# SIMG301M114LGH register map
Vendor: Silicon Labs; Series: Si; File version: B
Registers are 32-bit, read-write, reset 0x0 unless marked. A register's access mark holds for its fields unless they carry their own. Offsets are from the block's base; [hi:lo] are bit positions; {n}, {i} and the like mark numbered series; 'fields as' and 'values as' point back to an identical list.

## CMU_NS — CMU_NS Registers
Base 0x40804000
Same registers: CMU_S 0x50804000
0x00 IPVERSION ro reset 0x8
  [31:0] IPVERSION — IP Version ID
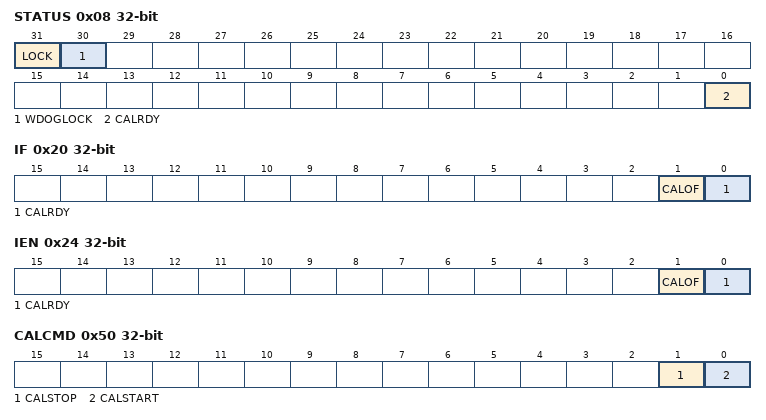
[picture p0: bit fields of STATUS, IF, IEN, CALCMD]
0x08 STATUS ro
  [31] LOCK — Configuration Lock Status
    0=UNLOCKED (Configuration lock is unlocked); 1=LOCKED (Configuration lock is locked)
  [30] WDOGLOCK — Configuration Lock Status for WDOG
    0=UNLOCKED (WDOG configuration lock is unlocked); 1=LOCKED (WDOG configuration lock is locked)
  [0] CALRDY — Calibration Ready
0x10 LOCK wo reset 0x93F7
  [15:0] LOCKKEY — Configuration Lock Key
    0x93F7=UNLOCK (Write this value to unlock)
0x14 WDOGLOCK wo reset 0x5257
  fields as LOCK
0x20 IF
  [1] CALOF — Calibration Overflow Interrupt Flag
  [0] CALRDY — Calibration Ready Interrupt Flag
0x24 IEN
  [1] CALOF — Calibration Overflow Interrupt Enable
  [0] CALRDY — Calibration Ready Interrupt Enable
0x50 CALCMD wo
  [1] CALSTOP — Calibration Stop
  [0] CALSTART — Calibration Start
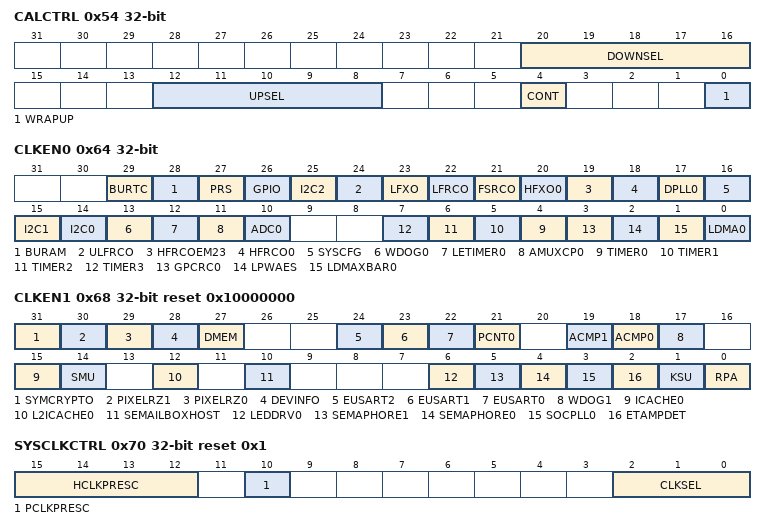
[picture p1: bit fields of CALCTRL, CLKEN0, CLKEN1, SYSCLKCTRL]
0x54 CALCTRL
  [20:16] DOWNSEL — Calibration Down-counter Select
    0=DISABLED (Down-counter is not clocked); 1=HCLK (HCLK is clocking down-counter); 2=PRS (PRS CMU_CALDN consumer is clocking down-counter); 3=HFXO (HFXO is clocking down-counter); 4=LFXO (LFXO is clocking down-counter); 5=HFRCODPLL (HFRCODPLL is clocking down-counter); 6=HFRCOEM23 (HFRCOEM23 is clocking down-counter); 7=FSRCO (FSRCO is clocking down-counter); 8=LFRCO (LFRCO is clocking down-counter); 9=ULFRCO (ULFRCO is clocking down-counter); 10=HFRCOLPW (HFRCOLPW is clocking down-counter); 11=SOCPLL (SOCPLL is clocking down-counter)
  [12:8] UPSEL — Calibration Up-counter Select
    0=DISABLED (Up-counter is not clocked); 1=HCLK (HCLK is clocking up-counter); 2=PRS (PRS is clocking down-counter); 3=HFXO (HFXO is clocking up-counter); 4=LFXO (LFXO is clocking up-counter); 5=HFRCODPLL (HFRCODPLL is clocking up-counter); 6=HFRCOEM23 (HFRCOEM23 is clocking up-counter); 7=FSRCO (FSRCO is clocking up-counter); 8=LFRCO (LFRCO is clocking up-counter); 9=ULFRCO (ULFRCO is clocking up-counter); 10=HFRCOLPW (HFRCOLPW is clocking up-counter); 11=SOCPLL (SOCPLL is clocking up-counter)
  [4] CONT — Continuous Calibration
  [0] WRAPUP — Wrap around Up-counter
0x58 CALCNT ro
  [23:0] CALCNT — Calibration Result Counter Value
0x5C CALTOP
  [23:0] CALTOP — Calibration Counter Top Value
0x64 CLKEN0
  [29] BURTC — Enable Bus Clock
  [28] BURAM — Enable Bus Clock
  [27] PRS — Enable Bus Clock
  [26] GPIO — Enable Bus Clock
  [25] I2C2 — Enable Bus Clock
  [24] ULFRCO — Enable Bus Clock
  [23] LFXO — Enable Bus Clock
  [22] LFRCO — Enable Bus Clock
  [21] FSRCO — Enable Bus Clock
  [20] HFXO0 — Enable Bus Clock
  [19] HFRCOEM23 — Enable Bus Clock
  [18] HFRCO0 — Enable Bus Clock
  [17] DPLL0 — Enable Bus Clock
  [16] SYSCFG — Enable Bus Clock
  [15] I2C1 — Enable Bus Clock
  [14] I2C0 — Enable Bus Clock
  [13] WDOG0 — Enable Bus Clock
  [12] LETIMER0 — Enable Bus Clock
  [11] AMUXCP0 — Enable Bus Clock
  [10] ADC0 — Enable Bus Clock
  [n+4] TIMER{n} (n=0..3) — Enable Bus Clock
  [3] GPCRC0 — Enable Bus Clock
  [2] LPWAES — Enable Bus Clock
  [1] LDMAXBAR0 — Enable Bus Clock
  [0] LDMA0 — Enable Bus Clock
0x68 CLKEN1 reset 0x10000000
  [31] SYMCRYPTO — Enable Bus Clock
  [30] PIXELRZ1 — Enable Bus Clock
  [29] PIXELRZ0 — Enable Bus Clock
  [28] DEVINFO — Enable Bus Clock
  [27] DMEM — Enable Bus Clock
  [24] EUSART2 — Enable Bus Clock
  [23] EUSART1 — Enable Bus Clock
  [22] EUSART0 — Enable Bus Clock
  [21] PCNT0 — Enable Bus Clock
  [19] ACMP1 — Enable Bus Clock
  [18] ACMP0 — Enable Bus Clock
  [17] WDOG1 — Enable Bus Clock
  [15] ICACHE0 — Enable Bus Clock
  [14] SMU — Enable Bus Clock
  [12] L2ICACHE0 — Enable Bus Clock
  [10] SEMAILBOXHOST — Enable Bus Clock
  [6] LEDDRV0 — Enable Bus Clock
  [5] SEMAPHORE1 — Enable Bus Clock
  [4] SEMAPHORE0 — Enable Bus Clock
  [3] SOCPLL0 — Enable Bus Clock
  [2] ETAMPDET — Enable Bus Clock
  [1] KSU — Enable Bus Clock
  [0] RPA — Enable Bus Clock
0x70 SYSCLKCTRL reset 0x1
  [15:12] HCLKPRESC — HCLK Prescaler
    0=DIV1 (HCLK is SYSCLK divided by 1); 1=DIV2 (HCLK is SYSCLK divided by 2); 3=DIV4 (HCLK is SYSCLK divided by 4); 7=DIV8 (HCLK is SYSCLK divided by 8); 15=DIV16 (HCLK is SYSCLK divided by 16)
  [10] PCLKPRESC — PCLK Prescaler
    0=DIV1 (PCLK is HCLK divided by 1); 1=DIV2 (PCLK is HCLK divided by 2)
  [2:0] CLKSEL — Clock Select
    1=FSRCO (FSRCO is clocking SYSCLK); 2=HFRCODPLL (HFRCODPLL is clocking SYSCLK); 3=HFXO (HFXO is clocking SYSCLK); 4=CLKIN0 (CLKIN0 is clocking SYSCLK); 5=SOCPLL (SOCPLL is clocking SYSCLK)
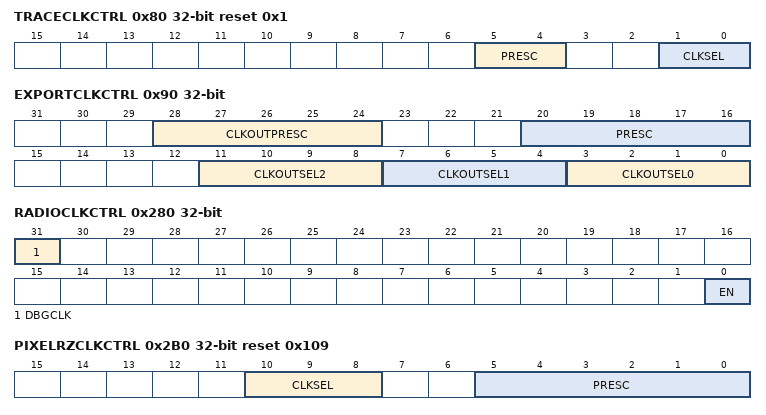
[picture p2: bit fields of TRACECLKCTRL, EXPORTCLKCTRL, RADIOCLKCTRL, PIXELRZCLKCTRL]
0x80 TRACECLKCTRL reset 0x1
  [5:4] PRESC — TRACECLK Prescaler
    0=DIV1 (TRACECLK is selected clock source divided by 1); 1=DIV2 (TRACECLK is selected clock source divided by 2); 2=DIV3 (TRACECLK is SYSCLK divided by 3); 3=DIV4 (TRACECLK is selected clock source divided by 4)
  [1:0] CLKSEL — Clock Select
    0=DISABLE (TRACE clock is disable); 1=SYSCLK (SYSCLK is driving TRACE); 2=HFRCOEM23 (HFRCOEM23 is driving TRACE); 3=HFRCODPLLRT (HFRCODPLLRT is driving TRACE)
0x90 EXPORTCLKCTRL
  [28:24] CLKOUTPRESC — CLKOUT Prescaler
  [20:16] PRESC — EXPORTCLK Prescaler
  [11:8] CLKOUTSEL2 — Clock Output Select 2
    0=DISABLED (CLKOUT2 is not clocked); 1=HCLK (HCLK is clocking CLKOUT2); 2=HFEXPCLK (EXPORTCLK is clocking CLKOUT2); 3=ULFRCO (ULFRCO is clocking CLKOUT2); 4=LFRCO (LFRCO is clocking CLKOUT2); 5=LFXO (LFXO is clocking CLKOUT2); 6=HFRCODPLL (HFRCODPLL is clocking CLKOUT2); 7=HFXO (HFXO is clocking CLKOUT2); 8=FSRCO (FSRCO is clocking CLKOUT2); 9=HFRCOEM23 (HFRCOEM23 is clocking CLKOUT2); 10=SOCPLL (SOCPLL is clocking CLKOUT2)
  [7:4] CLKOUTSEL1 — Clock Output Select 1
    0=DISABLED (CLKOUT1 is not clocked); 1=HCLK (HCLK is clocking CLKOUT1); 2=HFEXPCLK (EXPORTCLK is clocking CLKOUT1); 3=ULFRCO (ULFRCO is clocking CLKOUT1); 4=LFRCO (LFRCO is clocking CLKOUT1); 5=LFXO (LFXO is clocking CLKOUT1); 6=HFRCODPLL (HFRCODPLL is clocking CLKOUT1); 7=HFXO (HFXO is clocking CLKOUT1); 8=FSRCO (FSRCO is clocking CLKOUT1); 9=HFRCOEM23 (HFRCOEM23 is clocking CLKOUT1); 10=SOCPLL (SOCPLL is clocking CLKOUT1)
  [3:0] CLKOUTSEL0 — Clock Output Select 0
    0=DISABLED (CLKOUT0 is not clocked); 1=HCLK (HCLK is clocking CLKOUT0); 2=HFEXPCLK (EXPORTCLK is clocking CLKOUT0); 3=ULFRCO (ULFRCO is clocking CLKOUT0); 4=LFRCO (LFRCO is clocking CLKOUT0); 5=LFXO (LFXO is clocking CLKOUT0); 6=HFRCODPLL (HFRCODPLL is clocking CLKOUT0); 7=HFXO (HFXO is clocking CLKOUT0); 8=FSRCO (FSRCO is clocking CLKOUT0); 9=HFRCOEM23 (HFRCOEM23 is clocking CLKOUT0); 10=SOCPLL (SOCPLL is clocking CLKOUT0)
0x100 DPLLREFCLKCTRL
  [1:0] CLKSEL — Clock Select
    0=DISABLED (DPLLREFCLK is not clocked); 1=HFXO (HFXO is clocking DPLLREFCLK); 2=LFXO (LFXO is clocking DPLLREFCLK); 3=CLKIN0 (CLKIN0 is clocking DPLLREFCLK)
0x120 EM01GRPACLKCTRL reset 0x1
  [2:0] CLKSEL — Clock Select
    1=HFRCODPLL (HFRCODPLL is clocking EM01GRPACLK); 2=HFXO (HFXO is clocking EM01GRPACLK); 3=FSRCO (FSRCO is clocking EM01GRPACLK); 4=HFRCOEM23 (HFRCOEM23 is clocking EM01GRPACLK); 5=HFRCODPLLRT (HFRCODPLL (retimed) is clocking EM01GRPACLK. Check with datasheet for frequency limitation when using retiming with voltage scaling.); 6=HFXORT (HFXO (retimed) is clocking EM01GRPACLK. Check with datasheet for frequency limitation when using retiming with voltage scaling.)
0x128 EM01GRPCCLKCTRL reset 0x1
  [2:0] CLKSEL — Clock Select
    1=HFRCODPLL (HFRCODPLL is clocking EM01GRPCCLK); 2=HFXO (HFXO is clocking EM01GRPCCLK); 3=FSRCO (FSRCO is clocking EM01GRPCCLK); 4=HFRCOEM23 (HFRCOEM23 is clocking EM01GRPCCLK); 5=HFRCODPLLRT (HFRCODPLL (retimed) is clocking EM01GRPCCLK. Check with datasheet for frequency limitation when using retiming with voltage scaling.); 6=HFXORT (HFXO (retimed) is clocking EM01GRPCCLK. Check with datasheet for frequency limitation when using retiming with voltage scaling.)
0x140 EM23GRPACLKCTRL reset 0x1
  [1:0] CLKSEL — Clock Select
    1=LFRCO (LFRCO is clocking EM23GRPACLK); 2=LFXO (LFXO is clocking EM23GRPACLK); 3=ULFRCO (ULFRCO is clocking EM23GRPACLK)
0x160 EM4GRPACLKCTRL reset 0x1
  [1:0] CLKSEL — Clock Select
    1=LFRCO (LFRCO is clocking EM4GRPACLK); 2=LFXO (LFXO is clocking EM4GRPACLK); 3=ULFRCO (ULFRCO is clocking EM4GRPACLK)
0x180 ADCCLKCTRL reset 0x1
  [1:0] CLKSEL — Clock Select
    1=EM01GRPACLK (EM01GRPACLK is clocking ADCCLK); 2=FSRCO (FSRCO is clocking ADCCLK); 3=HFRCOEM23 (HFRCOEM23 is clocking ADCCLK)
0x200 WDOG0CLKCTRL reset 0x1
  [2:0] CLKSEL — Clock Select
    1=LFRCO (LFRCO is clocking WDOG0CLK); 2=LFXO (LFXO is clocking WDOG0CLK); 3=ULFRCO (ULFRCO is clocking WDOG0CLK); 4=HCLKDIV1024 (HCLKDIV1024 is clocking WDOG0CLK)
0x220 EUSART0CLKCTRL reset 0x1
  [2:0] CLKSEL — Clock Select
    0=DISABLED (EUSART0 is not clocked); 1=EM01GRPCCLK (EM01GRPCCLK is clocking EUSART0); 2=HFRCOEM23 (HFRCOEM23 is clocking EUSART0); 3=LFRCO (LFRCO is clocking EUSART0); 4=LFXO (LFXO is clocking EUSART0)
0x240 SYSRTC0CLKCTRL reset 0x1
  [1:0] CLKSEL — Clock Select
    1=LFRCO (LFRCO is clocking SYSRTC0CLK); 2=LFXO (LFXO is clocking SYSRTC0CLK); 3=ULFRCO (ULFRCO is clocking SYSRTC0CLK)
0x270 PCNT0CLKCTRL reset 0x1
  [1:0] CLKSEL — Clock Select
    0=DISABLED (PCNT0 is not clocked); 1=EM23GRPACLK (EM23GRPACLK is clocking PCNT0); 2=PCNTS0 (External pin PCNT_S0 is clocking PCNT0)
0x280 RADIOCLKCTRL
  [31] DBGCLK — Enable Clock for Debugger
  [0] EN — Enable
0x29C HFXO0LFCLKCTRL reset 0x1
  [1:0] CLKSEL — Clock Select
    0=DISABLED (HFXO0 LF clock is not generated); 1=LFXO (LFXO is clocking for startup time measurement); 2=LFRCO (LFRCO is clocking for startup time measurement)
0x2A8 EM01GRPDCLKCTRL reset 0x1
  [2:0] CLKSEL — Clock Select
    1=HFRCODPLL (HFRCODPLL is clocking EM01GRPDCLK); 2=HFXO (HFXO is clocking EM01GRPDCLK); 3=FSRCO (FSRCO is clocking EM01GRPDCLK); 4=HFRCOEM23 (HFRCOEM23 is clocking EM01GRPDCLK)
0x2AC I2C0CLKCTRL reset 0x1
  [2:0] CLKSEL — Clock Select
    0=DISABLED (I2C0 is not clocked); 1=EM01GRPDCLK (EM01GRPCCLK is clocking I2C0); 2=HFRCOEM23 (HFRCOEM23 is clocking I2C0); 3=LFRCO (LFRCO is clocking I2C0); 4=LFXO (LFXO is clocking I2C0)
0x2B0 PIXELRZCLKCTRL reset 0x109
  [10:8] CLKSEL — Clock Select
    1=HFRCODPLL (HFRCODPLL is clocking PIXELRZ0/1); 2=HFXO (HFXO is clocking PIXELRZ0/1); 3=FSRCO (FSRCO is clocking PIXELRZ0/1); 4=HFRCOEM23 (HFRCOEM23 is clocking PIXELRZ0/1)
  [5:0] PRESC — PIXELRZ Clock Prescaler
    {v}=DIV{v+1} (PIXELRZ clock divided by {v+1}) (v=0..3); 9=DIV10 (PIXELRZ clock divided by 10); 15=DIV16 (PIXELRZ clock divided by 16)
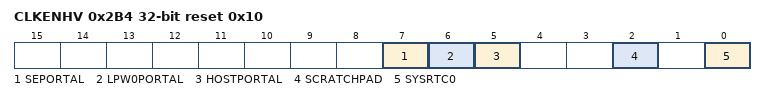
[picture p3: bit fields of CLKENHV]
0x2B4 CLKENHV reset 0x10
  [7] SEPORTAL — Enable Bus Clock
  [6] LPW0PORTAL — Enable Bus Clock
  [5] HOSTPORTAL — Enable Bus Clock
  [2] SCRATCHPAD — Enable Bus Clock
  [0] SYSRTC0 — Enable Bus Clock
